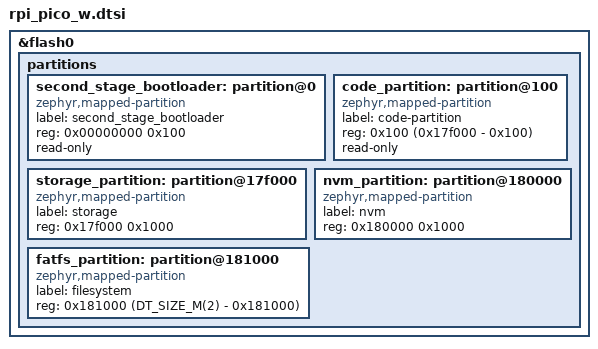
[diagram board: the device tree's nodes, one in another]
/* RP2040 UF2-native layout (no mcuboot): applied to the application image only.
 *
 * RP2040 W (Raspberry Pi Pico W): the CYW43 WiFi blob is linked into the
 * CircuitPython image, so the code partition grows from 1016 KB (the non-W
 * rpi_pico) to 1532 KB here. Flash is 2 MB.
 *
 * sysbuild.cmake picks this dtsi over dts/rpi_pico.dtsi when BOARD is
 * rpi_pico/rp2040/w, by trying MCUBOOT_LAYOUT_rpi_pico_rp2040_w before
 * MCUBOOT_LAYOUT_rpi_pico.
 */
&flash0 {
	/delete-node/ partitions;

	partitions {
		ranges;
		#address-cells = <1>;
		#size-cells = <1>;

		/* Reserved memory for the second stage bootloader */
		second_stage_bootloader: partition@0 {
			compatible = "zephyr,mapped-partition";
			label = "second_stage_bootloader";
			reg = <0x00000000 0x100>;
			read-only;
		};

		code_partition: partition@100 {
			compatible = "zephyr,mapped-partition";
			label = "code-partition";
			reg = <0x100 (0x17f000 - 0x100)>;
			read-only;
		};

		storage_partition: partition@17f000 {
			compatible = "zephyr,mapped-partition";
			label = "storage";
			reg = <0x17f000 0x1000>;
		};

		nvm_partition: partition@180000 {
			compatible = "zephyr,mapped-partition";
			label = "nvm";
			reg = <0x180000 0x1000>;
		};

		fatfs_partition: partition@181000 {
			compatible = "zephyr,mapped-partition";
			label = "filesystem";
			reg = <0x181000 (DT_SIZE_M(2) - 0x181000)>;
		};
	};
};
